# CM_CORE__CAM register map
Vendor: Texas Instruments
Peripheral module from a debugger description file (folder am574x).
Registers are 32-bit, access per field, reset 0x70000 unless marked. A register's access mark holds for its fields unless they carry their own. Offsets are as the file gives them; lines under a group give offsets from that group; [hi:lo] are bit positions; {n}, {i} and the like mark numbered series; 'fields as' and 'values as' point back to an identical list; <NAME> marks a mode.

## CM_CORE__CAM
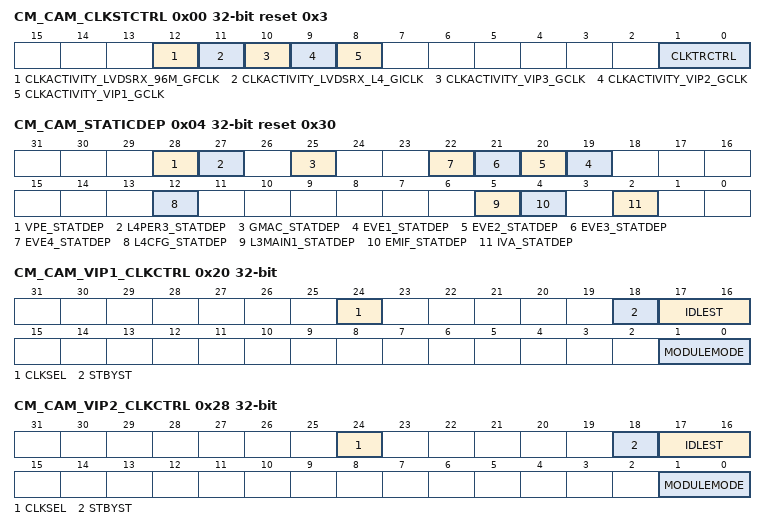
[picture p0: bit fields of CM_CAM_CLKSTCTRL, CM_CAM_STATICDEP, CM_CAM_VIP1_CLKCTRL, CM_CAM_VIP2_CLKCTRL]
0x00 CM_CAM_CLKSTCTRL reset 0x3 — This register enables the domain power state transition. It controls the HW supervised domain power state transition between ON-ACTIVE and ON-INACTIVE states. It also hold one status bit per clock input of the domain.
  [12] CLKACTIVITY_LVDSRX_96M_GFCLK ro — This field indicates the state of the LVDSRX_96M_GFCLK clock input of the domain. [warm reset insensitive]
  [11] CLKACTIVITY_LVDSRX_L4_GICLK ro — This field indicates the state of the LVDSRX_L4_GICLK clock input of the domain. [warm reset insensitive]
    0=Corresponding_clock_is_definitely_gated; 1=Corresponding clock is running or gating/ungating transition is on-going
  [10] CLKACTIVITY_VIP3_GCLK ro — This field indicates the state of the VIP3_GCLK clock input of the domain. [warm reset insensitive] Note: VIP3_GCLK is used as functional clock to the CAL module in this family of devices.
    0=INACT (Corresponding clock is definitely gated); 1=ACT (Corresponding clock is running or gating/ungating transition is on-going)
  [9] CLKACTIVITY_VIP2_GCLK ro — This field indicates the state of the VIP2_GCLK clock input of the domain. [warm reset insensitive]
    values as CLKACTIVITY_VIP3_GCLK
  [8] CLKACTIVITY_VIP1_GCLK ro — This field indicates the state of the VIP1_GCLK clock input of the domain. [warm reset insensitive]
    values as CLKACTIVITY_VIP3_GCLK
  [1:0] CLKTRCTRL rw — Controls the clock state transition of the CAM clock domain.
    0=NO_SLEEP (NO_SLEEP: Sleep transition cannot be initiated. Wakeup transition may however occur.); 1=SW_SLEEP (SW_SLEEP: Start a software forced sleep transition on the domain.); 2=SW_WKUP (SW_WKUP: Start a software forced wake-up transition on the domain.); 3=HW_AUTO (HW_AUTO: Automatic transition is enabled. Sleep and wakeup transition are based upon hardware conditions.)
0x04 CM_CAM_STATICDEP reset 0x30 — This register controls the static domain depedencies from CAM domain towards 'target' domains. It is relevant only for domain having system initiator(s).
  [28] VPE_STATDEP rw — Static dependency towards VPE clock domain
    0=DISABLED (Dependency is disabled); 1=ENABLED (Dependency is enabled)
  [27] L4PER3_STATDEP rw — Static dependency towards L4PER3 clock domain
    values as VPE_STATDEP
  [25] GMAC_STATDEP rw — Static dependency towards GMAC clock domain
    values as VPE_STATDEP
  [n+18] EVE{n}_STATDEP rw (n=1..4) — Static dependency towards EVE{n} clock domain
    values as VPE_STATDEP
  [12] L4CFG_STATDEP ro — Static dependency towards L4CFG clock domain
    0=DISABLED (Dependency is disabled)
  [5] L3MAIN1_STATDEP ro — Static dependency towards L3MAIN1 clock domain
    1=ENABLED (Dependency is enabled)
  [4] EMIF_STATDEP rw — Static dependency towards EMIF clock domain
    values as VPE_STATDEP
  [2] IVA_STATDEP rw — Static dependency towards IVA clock domain
    values as VPE_STATDEP
0x20 CM_CAM_VIP1_CLKCTRL — This register manages the VIP1 clocks.
  [24] CLKSEL rw — Selects functional clock for VIP between L3_ICLK and CORE_ISS_MAIN_CLK
    0=SEL_L3_ICLK (Selects L3_ICLK); 1=SEL_CORE_ISS_MAIN_CLK (Selects CORE_ISS_MAIN_CLK)
  [18] STBYST ro — Module standby status. [warm reset insensitive]
    0=FUNC (Module is functional (not in standby)); 1=STANDBY (Module is in standby)
  [17:16] IDLEST ro — Module idle status. [warm reset insensitive]
    0=FUNC (Module is fully functional, including OCP); 1=TRANS (Module is performing transition: wakeup, or sleep, or sleep abortion); 2=IDLE (Module is in Idle mode (only OCP part). It is functional if using separate functional clock); 3=DISABLE (Module is disabled and cannot be accessed)
  [1:0] MODULEMODE rw — Control the way mandatory clocks are managed.
    0=DISABLED (Module is disabled by SW. Any OCP access to module results in an error, except if resulting from a module wakeup (asynchronous wakeup).); 1=AUTO (Module is managed automatically by HW according to clock domain transition. A clock domain sleep transition put module into idle. A wakeup domain transition put it back into function. If CLKTRCTRL=3, any OCP access to module is always granted. Module clocks may be gated according to the clock domain state.)
0x28 CM_CAM_VIP2_CLKCTRL — This register manages the VIP2 clocks.
  fields as CM_CAM_VIP1_CLKCTRL
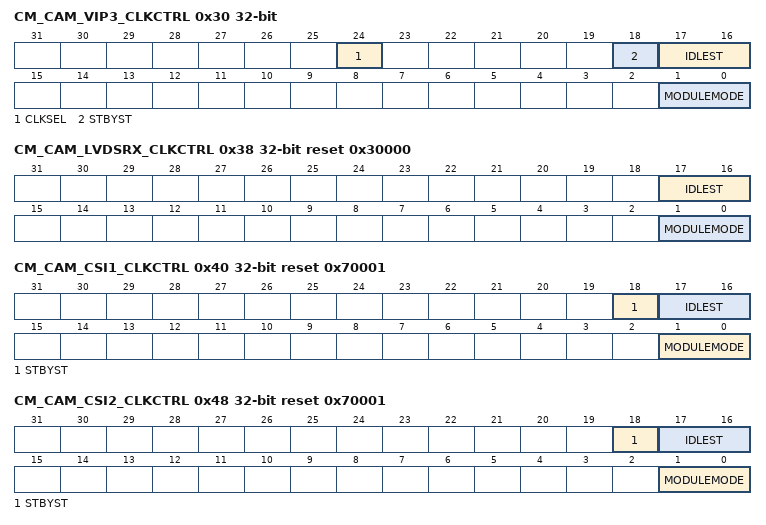
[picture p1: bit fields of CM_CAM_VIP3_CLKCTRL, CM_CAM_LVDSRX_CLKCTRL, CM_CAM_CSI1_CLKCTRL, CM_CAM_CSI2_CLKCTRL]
0x30 CM_CAM_VIP3_CLKCTRL — This register manages the clocks.
  [24] CLKSEL rw — Selects functional clock forCAL between L3_ICLK and CORE_ISS_MAIN_CLK
    values as CM_CAM_VIP1_CLKCTRL.CLKSEL
  [18] STBYST ro — Module standby status. [warm reset insensitive] Standby protocol is not supported for CAL module in this family of devices.
    values as CM_CAM_VIP1_CLKCTRL.STBYST
  [17:16] IDLEST ro — Module idle status. [warm reset insensitive] This bit indicates the Idle status of the CAL module in this family of devices.
    values as CM_CAM_VIP1_CLKCTRL.IDLEST
  [1:0] MODULEMODE rw — Control the way mandatory clocks are managed.
    values as CM_CAM_VIP1_CLKCTRL.MODULEMODE
0x38 CM_CAM_LVDSRX_CLKCTRL reset 0x30000 — This register manages the LVDSRX clocks.
  [17:16] IDLEST ro — Module idle status. [warm reset insensitive]
    0=FUNC (Module is fully functional, including OCP); 1=TRANS (Module is performing transition: wakeup, or sleep, or sleep abortion); 3=DISABLE (Module is disabled and cannot be accessed); 2=IDLE (Module is in Idle mode (only OCP part). It is functional if using separate functional clock)
  [1:0] MODULEMODE rw — Control the way mandatory clocks are managed.
    0=DISABLED (Module is disabled by SW. Any OCP access to module results in an error, except if resulting from a module wakeup (asynchronous wakeup).); 2=ENABLE (Module is explicitly enabled. Interface clock (if not used for functions) may be gated according to the clock domain state. Functional clocks are guarantied to stay present. As long as in this configuration, power domain sleep transition cannot happen.)
0x40 CM_CAM_CSI1_CLKCTRL ro reset 0x70001 — This register manages the CSI1 clocks.
  [18] STBYST — Module standby status. [warm reset insensitive]
    values as CM_CAM_VIP1_CLKCTRL.STBYST
  [17:16] IDLEST — Module idle status. [warm reset insensitive]
    values as CM_CAM_LVDSRX_CLKCTRL.IDLEST
  [1:0] MODULEMODE — Control the way mandatory clocks are managed.
    1=AUTO (Module is managed automatically by HW according to clock domain transition. A clock domain sleep transition put module into idle. A wakeup domain transition put it back into function. If CLKTRCTRL=3, any OCP access to module is always granted. Module clocks may be gated according to the clock domain state.)
0x48 CM_CAM_CSI2_CLKCTRL ro reset 0x70001 — This register manages the CSI2 clocks.
  fields as CM_CAM_CSI1_CLKCTRL
